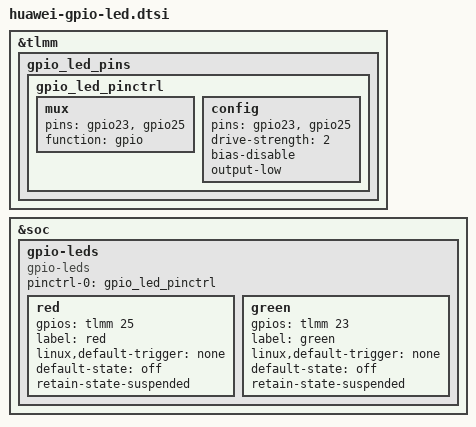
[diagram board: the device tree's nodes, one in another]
&tlmm {
	gpio_led_pins {
		gpio_led_pinctrl: gpio_led_pinctrl {
			mux {
				pins = "gpio23", "gpio25";
				function = "gpio";
			};

			config {
				pins = "gpio23", "gpio25";
				drive-strength = <2>;
				bias-disable;
				output-low;
			};
		};
	};

};

&soc {
	gpio-leds {
		compatible = "gpio-leds";
		status = "okay";
		pinctrl-names = "default";
		pinctrl-0 = <&gpio_led_pinctrl>;

		red {
			gpios = <&tlmm 25 0>;
			label = "red";
			linux,default-trigger = "none";
			default-state = "off";
			retain-state-suspended;
		};

		green {
			gpios = <&tlmm 23 0>;
			label = "green";
			linux,default-trigger = "none";
			default-state = "off";
			retain-state-suspended;
		};
	};
};
